# netx90_app register map
File version: 1.0
CPU: CM4 r0p1, little endian, MPU, FPU, 4 interrupt priority bits, 78 interrupts
Registers are 32-bit, read-write, reset 0x0 unless marked. A register's access mark holds for its fields unless they carry their own. Offsets are from the block's base; [hi:lo] are bit positions; {n}, {i} and the like mark numbered series; 'fields as' and 'values as' point back to an identical list.

## pad_ctrl
Base 0xFF401000
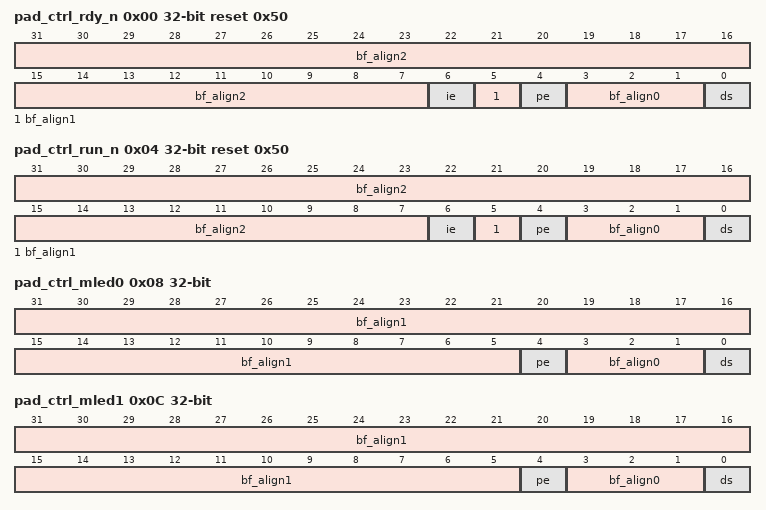
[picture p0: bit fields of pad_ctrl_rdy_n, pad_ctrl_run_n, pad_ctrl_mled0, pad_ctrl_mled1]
0x00 pad_ctrl_rdy_n reset 0x50 (reset mask 0x51) — Pad configuration register of port RDY_N (asic_ctrl_access_key protected). Pad type: PRUW0408SCDG_33 This register is protected by the netX access-key mechanism; changing this register is only possible by the following sequence: 1.: read out access-key from asic_ctrl_access_key register 2.: write back access-key to asic_ctrl_access_key register 3.: write desired value to this register Programable pad functions are: ds: Driving strength: 0: low driving strength (default), 1: high driving strength. pe: Pull enable: 0: No resistor is applied, 1: resistor is enabled. The pull-direction (up or down) is determined by the pad-type. ie: Input enable: 0: Digital pad input function disabled, 1: input is enabled. Note: Not all functions are available for all pads, it depends on the pad type. Functions not found as programmable bit in the register of a pad are not supported by the pad. Note: During a power cycle (power up or when a power watch detects an invalid supply), all IOs are undriven (output enable is off). Additionally the following states are forced to the IOs (POC-states): pe: 0 Attention: the internal push/pull resistors are not applied during a power cycle. ds: 1 (no impact as outputs are disabled) ie: 0 (no impact as core is in reset) After all power watches have detected a stable power state, the netX enters the reset state. At that moment the default values of the PAD_CTRL registers will be applied to the IOs.
  [31:7] bf_align2 — bitField alignment value for aeabi compatibility
  [6] ie — input enable (enabled by default)
  [5] bf_align1 — bitField alignment value for aeabi compatibility
  [4] pe — pull enable (pull-up pad, enabled by default)
  [3:1] bf_align0 — bitField alignment value for aeabi compatibility
  [0] ds — driving strength (low by default)
0x04 pad_ctrl_run_n reset 0x50 (reset mask 0x51) — Pad configuration register of port RUN_N (asic_ctrl_access_key protected). Pad type: PRUW0408SCDG_33 For details refer to description of register pad_ctrl_rdy_n.
  fields as pad_ctrl_rdy_n
0x08 pad_ctrl_mled0 (reset mask 0x11) — Pad configuration register of port MLED0 (asic_ctrl_access_key protected). Pad type: PRDW0408CDG_33(o_sc) For details refer to description of register pad_ctrl_rdy_n.
  [31:5] bf_align1 — bitField alignment value for aeabi compatibility
  [4] pe — pull enable (pull-down pad, disabled by default)
  [3:1] bf_align0 — bitField alignment value for aeabi compatibility
  [0] ds — driving strength (low by default)
0x0C pad_ctrl_mled1 (reset mask 0x11) — Pad configuration register of port MLED1 (asic_ctrl_access_key protected). Pad type: PRDW0408CDG_33(o_sc) For details refer to description of register pad_ctrl_rdy_n.
  fields as pad_ctrl_mled0
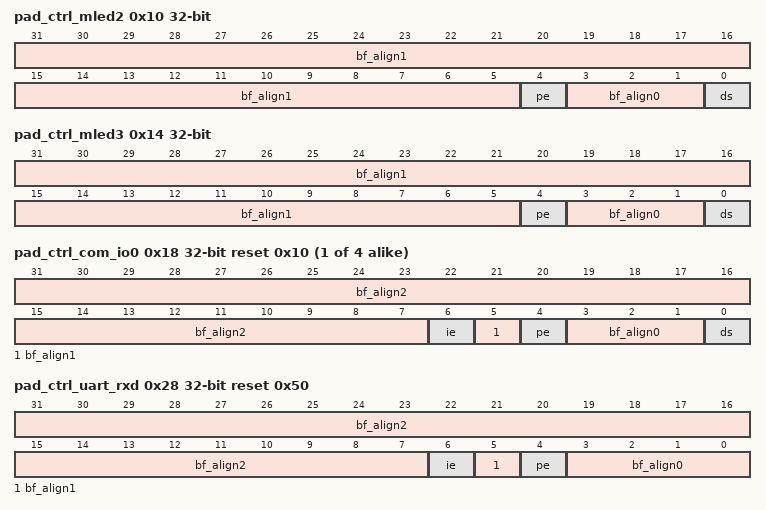
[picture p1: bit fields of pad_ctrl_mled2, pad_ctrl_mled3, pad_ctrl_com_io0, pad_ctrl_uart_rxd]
0x10 pad_ctrl_mled2 (reset mask 0x11) — Pad configuration register of port MLED2 (asic_ctrl_access_key protected). Pad type: PRDW0408CDG_33(o) For details refer to description of register pad_ctrl_rdy_n.
  fields as pad_ctrl_mled0
0x14 pad_ctrl_mled3 (reset mask 0x11) — Pad configuration register of port MLED3 (asic_ctrl_access_key protected). Pad type: PRDW0408CDG_33(o) For details refer to description of register pad_ctrl_rdy_n.
  fields as pad_ctrl_mled0
{0x18+4i} pad_ctrl_com_io{i} reset 0x10 (reset mask 0x51) (i=0..3) — Pad configuration register of port COM_IO{i} (asic_ctrl_access_key protected). Pad type: PRDW0408SCDG_ANA_SW_33(adc3) For details refer to description of register pad_ctrl_rdy_n.
  [31:7] bf_align2 — bitField alignment value for aeabi compatibility
  [6] ie — input enable (shared analog function, disabled by default)
  [5] bf_align1 — bitField alignment value for aeabi compatibility
  [4] pe — pull enable (pull-down pad, enabled by default)
  [3:1] bf_align0 — bitField alignment value for aeabi compatibility
  [0] ds — driving strength (low by default)
0x28 pad_ctrl_uart_rxd reset 0x50 (reset mask 0x50) — Pad configuration register of port UART_RXD (asic_ctrl_access_key protected). Pad type: PDDW0204SCDG_33(i) For details refer to description of register pad_ctrl_rdy_n.
  [31:7] bf_align2 — bitField alignment value for aeabi compatibility
  [6] ie — input enable (enabled by default)
  [5] bf_align1 — bitField alignment value for aeabi compatibility
  [4] pe — pull enable (pull-down pad, enabled by default)
  [3:0] bf_align0 — bitField alignment value for aeabi compatibility
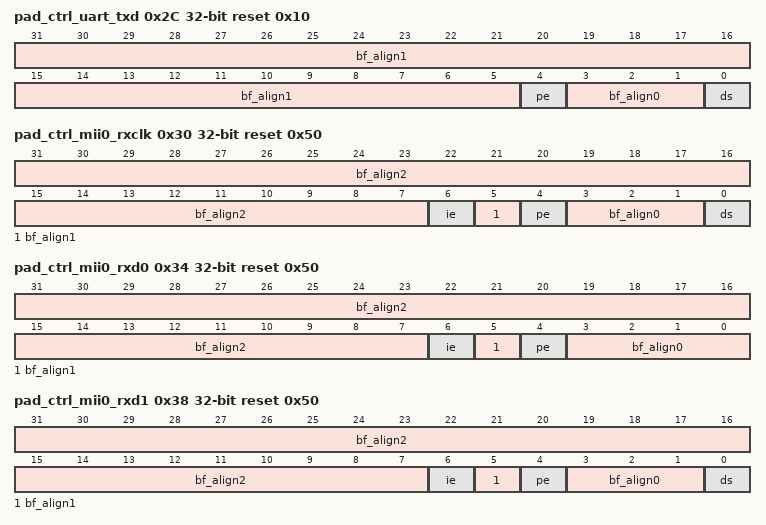
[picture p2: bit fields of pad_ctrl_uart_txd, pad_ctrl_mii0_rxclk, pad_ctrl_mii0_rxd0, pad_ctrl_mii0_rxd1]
0x2C pad_ctrl_uart_txd reset 0x10 (reset mask 0x11) — Pad configuration register of port UART_TXD (asic_ctrl_access_key protected). Pad type: PRDW0408CDG_33(o) For details refer to description of register pad_ctrl_rdy_n.
  [31:5] bf_align1 — bitField alignment value for aeabi compatibility
  [4] pe — pull enable (pull-down pad, enabled by default)
  [3:1] bf_align0 — bitField alignment value for aeabi compatibility
  [0] ds — driving strength (low by default)
0x30 pad_ctrl_mii0_rxclk reset 0x50 (reset mask 0x51) — Pad configuration register of port MII0_RXCLK (asic_ctrl_access_key protected). Pad type: PRDW0408SCDG_33 For details refer to description of register pad_ctrl_rdy_n.
  [31:7] bf_align2 — bitField alignment value for aeabi compatibility
  [6] ie — input enable (enabled by default)
  [5] bf_align1 — bitField alignment value for aeabi compatibility
  [4] pe — pull enable (pull-down pad, enabled by default)
  [3:1] bf_align0 — bitField alignment value for aeabi compatibility
  [0] ds — driving strength (low by default)
0x34 pad_ctrl_mii0_rxd0 reset 0x50 (reset mask 0x50) — Pad configuration register of port MII0_RXD0 (asic_ctrl_access_key protected). Pad type: PDDW0204SCDG_33(i) For details refer to description of register pad_ctrl_rdy_n.
  fields as pad_ctrl_uart_rxd
0x38 pad_ctrl_mii0_rxd1 reset 0x50 (reset mask 0x51) — Pad configuration register of port MII0_RXD1 (asic_ctrl_access_key protected). Pad type: PDDW0408SCDG_33 For details refer to description of register pad_ctrl_rdy_n.
  fields as pad_ctrl_mii0_rxclk
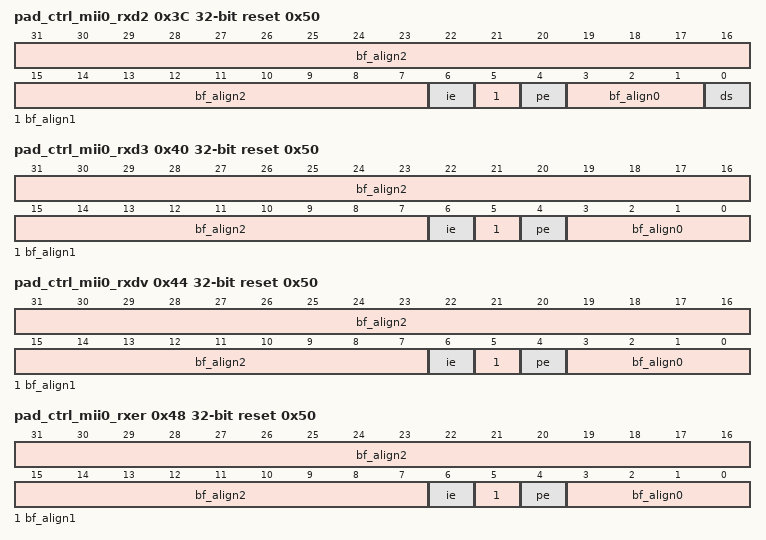
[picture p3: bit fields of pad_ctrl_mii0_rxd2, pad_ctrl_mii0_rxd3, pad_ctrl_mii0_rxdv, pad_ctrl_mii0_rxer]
0x3C pad_ctrl_mii0_rxd2 reset 0x50 (reset mask 0x51) — Pad configuration register of port MII0_RXD2 (asic_ctrl_access_key protected). Pad type: PRDW0408SCDG_33 For details refer to description of register pad_ctrl_rdy_n.
  fields as pad_ctrl_mii0_rxclk
0x40 pad_ctrl_mii0_rxd3 reset 0x50 (reset mask 0x50) — Pad configuration register of port MII0_RXD3 (asic_ctrl_access_key protected). Pad type: PDDW0204SCDG_33(i) For details refer to description of register pad_ctrl_rdy_n.
  fields as pad_ctrl_uart_rxd
0x44 pad_ctrl_mii0_rxdv reset 0x50 (reset mask 0x50) — Pad configuration register of port MII0_RXDV (asic_ctrl_access_key protected). Pad type: PDDW0204SCDG_33(i) For details refer to description of register pad_ctrl_rdy_n.
  fields as pad_ctrl_uart_rxd
0x48 pad_ctrl_mii0_rxer reset 0x50 (reset mask 0x50) — Pad configuration register of port MII0_RXER (asic_ctrl_access_key protected). Pad type: PDDW0204SCDG_33(i) For details refer to description of register pad_ctrl_rdy_n.
  fields as pad_ctrl_uart_rxd
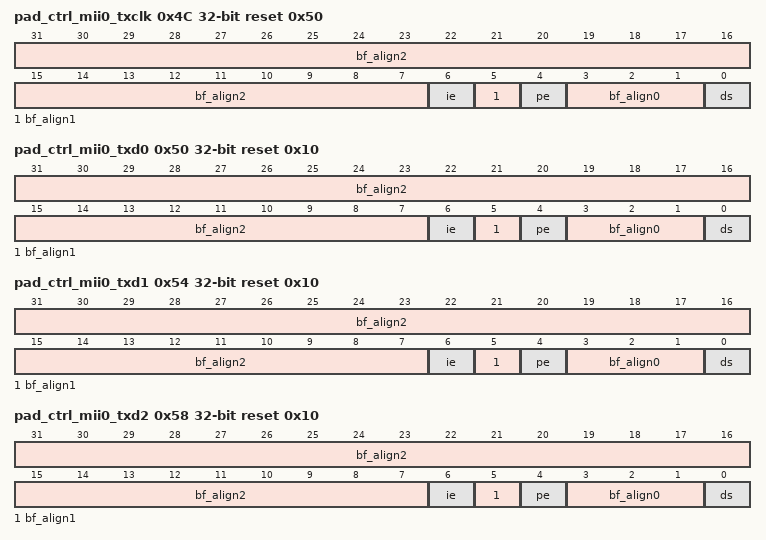
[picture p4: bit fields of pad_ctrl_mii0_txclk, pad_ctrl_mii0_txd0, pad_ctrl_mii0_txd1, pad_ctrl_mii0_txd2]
0x4C pad_ctrl_mii0_txclk reset 0x50 (reset mask 0x51) — Pad configuration register of port MII0_TXCLK (asic_ctrl_access_key protected). Pad type: PRDW0408SCDG_33 For details refer to description of register pad_ctrl_rdy_n.
  fields as pad_ctrl_mii0_rxclk
0x50 pad_ctrl_mii0_txd0 reset 0x10 (reset mask 0x51) — Pad configuration register of port MII0_TXD0 (asic_ctrl_access_key protected). Pad type: PRDW0408SCDG_ANA_SW_33(adc2) For details refer to description of register pad_ctrl_rdy_n.
  fields as pad_ctrl_com_io0
0x54 pad_ctrl_mii0_txd1 reset 0x10 (reset mask 0x51) — Pad configuration register of port MII0_TXD1 (asic_ctrl_access_key protected). Pad type: PRDW0408SCDG_ANA_SW_33(adc3) For details refer to description of register pad_ctrl_rdy_n.
  fields as pad_ctrl_com_io0
0x58 pad_ctrl_mii0_txd2 reset 0x10 (reset mask 0x51) — Pad configuration register of port MII0_TXD2 (asic_ctrl_access_key protected). Pad type: PRDW0408SCDG_ANA_SW_33(adc2) For details refer to description of register pad_ctrl_rdy_n.
  fields as pad_ctrl_com_io0
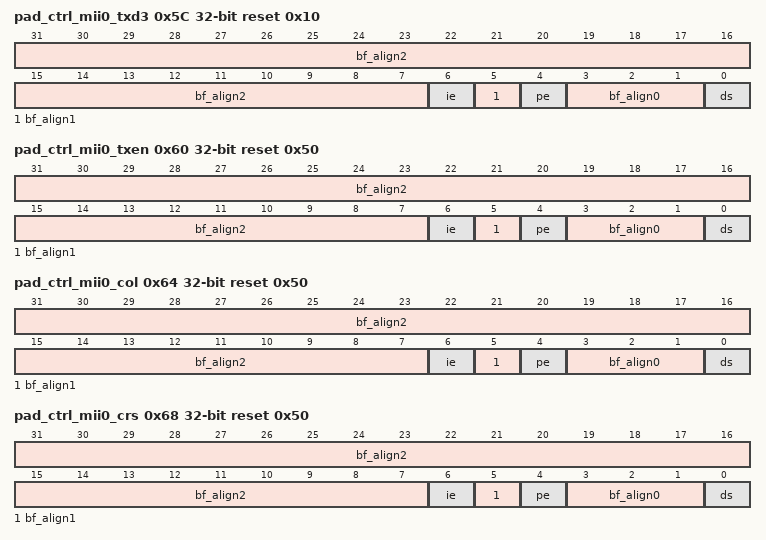
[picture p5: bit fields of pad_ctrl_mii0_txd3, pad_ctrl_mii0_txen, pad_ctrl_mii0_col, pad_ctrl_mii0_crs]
0x5C pad_ctrl_mii0_txd3 reset 0x10 (reset mask 0x51) — Pad configuration register of port MII0_TXD3 (asic_ctrl_access_key protected). Pad type: PRDW0408SCDG_ANA_SW_33(adc3) For details refer to description of register pad_ctrl_rdy_n.
  fields as pad_ctrl_com_io0
0x60 pad_ctrl_mii0_txen reset 0x50 (reset mask 0x51) — Pad configuration register of port MII0_TXEN (asic_ctrl_access_key protected). Pad type: PDDW0408SCDG_33 For details refer to description of register pad_ctrl_rdy_n.
  fields as pad_ctrl_mii0_rxclk
0x64 pad_ctrl_mii0_col reset 0x50 (reset mask 0x51) — Pad configuration register of port MII0_COL (asic_ctrl_access_key protected). Pad type: PDDW0408SCDG_33 For details refer to description of register pad_ctrl_rdy_n.
  fields as pad_ctrl_mii0_rxclk
0x68 pad_ctrl_mii0_crs reset 0x50 (reset mask 0x51) — Pad configuration register of port MII0_CRS (asic_ctrl_access_key protected). Pad type: PDDW0408SCDG_33 For details refer to description of register pad_ctrl_rdy_n.
  fields as pad_ctrl_mii0_rxclk
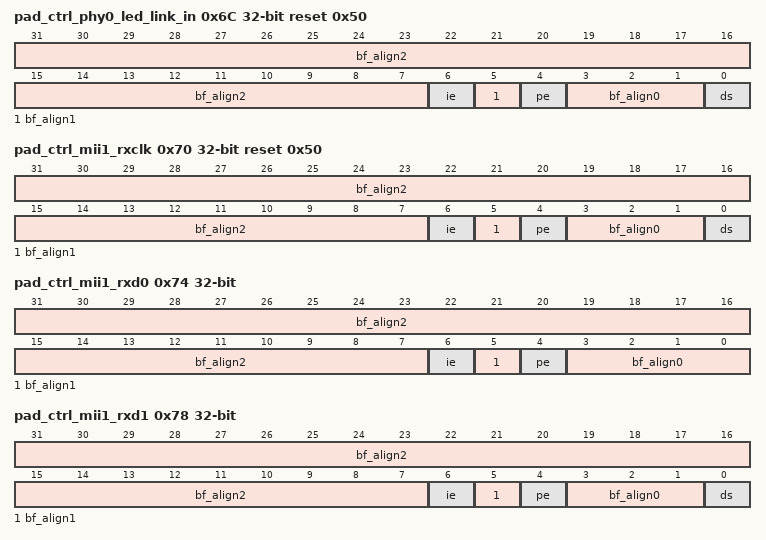
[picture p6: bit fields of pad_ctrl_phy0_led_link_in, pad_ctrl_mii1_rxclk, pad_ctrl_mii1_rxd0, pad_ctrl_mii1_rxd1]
0x6C pad_ctrl_phy0_led_link_in reset 0x50 (reset mask 0x51) — Pad configuration register of port PHY0_LED_LINK_IN (asic_ctrl_access_key protected). Pad type: PDDW0408SCDG_33 For details refer to description of register pad_ctrl_rdy_n.
  fields as pad_ctrl_mii0_rxclk
0x70 pad_ctrl_mii1_rxclk reset 0x50 (reset mask 0x51) — Pad configuration register of port MII1_RXCLK (asic_ctrl_access_key protected). Pad type: PRDW0408SCDG_33 For details refer to description of register pad_ctrl_rdy_n.
  fields as pad_ctrl_mii0_rxclk
0x74 pad_ctrl_mii1_rxd0 (reset mask 0x50) — Pad configuration register of port MII1_RXD0 (asic_ctrl_access_key protected). Pad type: PDDW0204SCDG_33(i_double_bond) For details refer to description of register pad_ctrl_rdy_n.
  [31:7] bf_align2 — bitField alignment value for aeabi compatibility
  [6] ie — input enable (disabled by default)
  [5] bf_align1 — bitField alignment value for aeabi compatibility
  [4] pe — pull enable (pull-down pad, disabled by default)
  [3:0] bf_align0 — bitField alignment value for aeabi compatibility
0x78 pad_ctrl_mii1_rxd1 (reset mask 0x51) — Pad configuration register of port MII1_RXD1 (asic_ctrl_access_key protected). Pad type: PDDW0408SCDG_33(double_bond) For details refer to description of register pad_ctrl_rdy_n.
  [31:7] bf_align2 — bitField alignment value for aeabi compatibility
  [6] ie — input enable (disabled by default)
  [5] bf_align1 — bitField alignment value for aeabi compatibility
  [4] pe — pull enable (pull-down pad, disabled by default)
  [3:1] bf_align0 — bitField alignment value for aeabi compatibility
  [0] ds — driving strength (low by default)
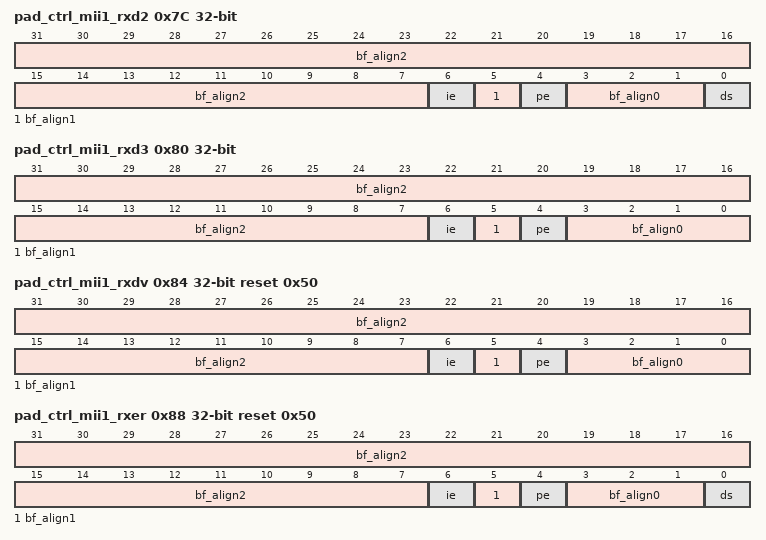
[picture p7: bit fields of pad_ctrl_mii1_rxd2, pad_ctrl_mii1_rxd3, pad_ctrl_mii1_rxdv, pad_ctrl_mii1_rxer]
0x7C pad_ctrl_mii1_rxd2 (reset mask 0x51) — Pad configuration register of port MII1_RXD2 (asic_ctrl_access_key protected). Pad type: PRDW0408SCDG_33(double_bond) For details refer to description of register pad_ctrl_rdy_n.
  fields as pad_ctrl_mii1_rxd1
0x80 pad_ctrl_mii1_rxd3 (reset mask 0x50) — Pad configuration register of port MII1_RXD3 (asic_ctrl_access_key protected). Pad type: PDDW0204SCDG_33(i_double_bond) For details refer to description of register pad_ctrl_rdy_n.
  fields as pad_ctrl_mii1_rxd0
0x84 pad_ctrl_mii1_rxdv reset 0x50 (reset mask 0x50) — Pad configuration register of port MII1_RXDV (asic_ctrl_access_key protected). Pad type: PDDW0204SCDG_33(i) For details refer to description of register pad_ctrl_rdy_n.
  fields as pad_ctrl_uart_rxd
0x88 pad_ctrl_mii1_rxer reset 0x50 (reset mask 0x51) — Pad configuration register of port MII1_RXER (asic_ctrl_access_key protected). Pad type: PDDW0408SCDG_33 For details refer to description of register pad_ctrl_rdy_n.
  fields as pad_ctrl_mii0_rxclk
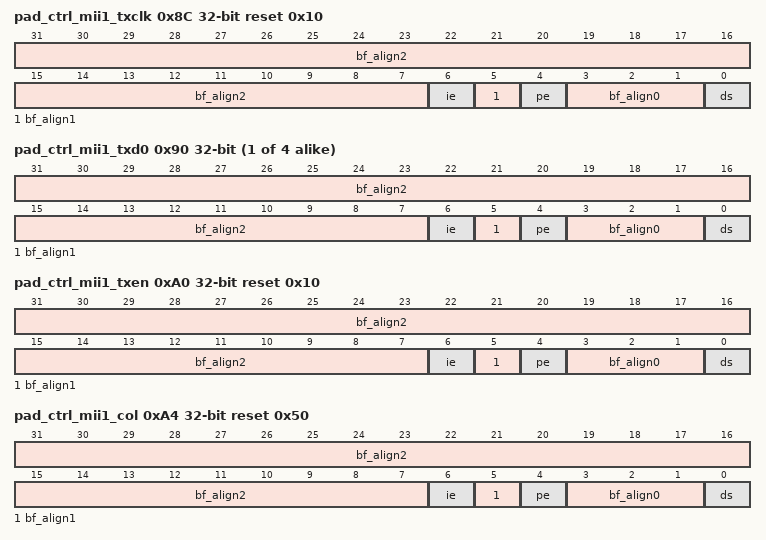
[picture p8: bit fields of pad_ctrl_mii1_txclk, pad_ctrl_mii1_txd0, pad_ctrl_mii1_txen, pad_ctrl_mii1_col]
0x8C pad_ctrl_mii1_txclk reset 0x10 (reset mask 0x51) — Pad configuration register of port MII1_TXCLK (asic_ctrl_access_key protected). Pad type: PRDW0408SCDG_ANA_SW_33(adc2) For details refer to description of register pad_ctrl_rdy_n.
  fields as pad_ctrl_com_io0
{0x90+4i} pad_ctrl_mii1_txd{i} (reset mask 0x51) (i=0..3) — Pad configuration register of port MII1_TXD{i} (asic_ctrl_access_key protected). Pad type: PRDW0408SCDG_33(double_bond) For details refer to description of register pad_ctrl_rdy_n.
  fields as pad_ctrl_mii1_rxd1
0xA0 pad_ctrl_mii1_txen reset 0x10 (reset mask 0x51) — Pad configuration register of port MII1_TXEN (asic_ctrl_access_key protected). Pad type: PRDW0408SCDG_ANA_SW_33(adc2) For details refer to description of register pad_ctrl_rdy_n.
  fields as pad_ctrl_com_io0
0xA4 pad_ctrl_mii1_col reset 0x50 (reset mask 0x51) — Pad configuration register of port MII1_COL (asic_ctrl_access_key protected). Pad type: PDDW0408SCDG_33 For details refer to description of register pad_ctrl_rdy_n.
  fields as pad_ctrl_mii0_rxclk
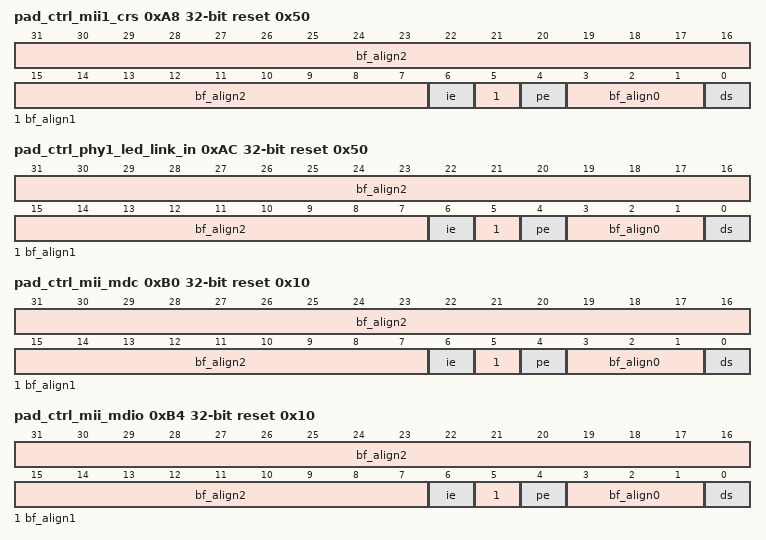
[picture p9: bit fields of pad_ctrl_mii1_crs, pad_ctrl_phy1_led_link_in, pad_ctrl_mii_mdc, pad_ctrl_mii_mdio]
0xA8 pad_ctrl_mii1_crs reset 0x50 (reset mask 0x51) — Pad configuration register of port MII1_CRS (asic_ctrl_access_key protected). Pad type: PDDW0408SCDG_33 For details refer to description of register pad_ctrl_rdy_n.
  fields as pad_ctrl_mii0_rxclk
0xAC pad_ctrl_phy1_led_link_in reset 0x50 (reset mask 0x51) — Pad configuration register of port PHY1_LED_LINK_IN (asic_ctrl_access_key protected). Pad type: PDDW0408SCDG_33 For details refer to description of register pad_ctrl_rdy_n.
  fields as pad_ctrl_mii0_rxclk
0xB0 pad_ctrl_mii_mdc reset 0x10 (reset mask 0x51) — Pad configuration register of port MII_MDC (asic_ctrl_access_key protected). Pad type: PRDW0408SCDG_ANA_SW_33(adc2) For details refer to description of register pad_ctrl_rdy_n.
  fields as pad_ctrl_com_io0
0xB4 pad_ctrl_mii_mdio reset 0x10 (reset mask 0x51) — Pad configuration register of port MII_MDIO (asic_ctrl_access_key protected). Pad type: PRDW0408SCDG_ANA_SW_33(adc2) For details refer to description of register pad_ctrl_rdy_n.
  fields as pad_ctrl_com_io0
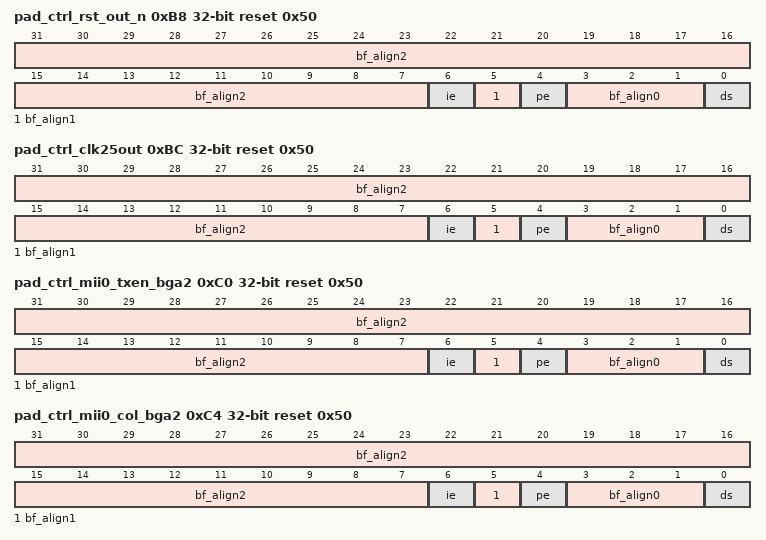
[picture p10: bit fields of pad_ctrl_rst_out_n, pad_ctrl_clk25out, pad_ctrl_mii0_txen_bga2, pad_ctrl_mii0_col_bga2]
0xB8 pad_ctrl_rst_out_n reset 0x50 (reset mask 0x51) — Pad configuration register of port RST_OUT_N (asic_ctrl_access_key protected). Pad type: PRDW0408SCDG_33 For details refer to description of register pad_ctrl_rdy_n.
  fields as pad_ctrl_mii0_rxclk
0xBC pad_ctrl_clk25out reset 0x50 (reset mask 0x51) — Pad configuration register of port CLK25OUT (asic_ctrl_access_key protected). Pad type: PDDW0408SCDG_33 For details refer to description of register pad_ctrl_rdy_n.
  fields as pad_ctrl_mii0_rxclk
0xC0 pad_ctrl_mii0_txen_bga2 reset 0x50 (reset mask 0x51) — Pad configuration register of port MII0_TXEN_BGA2 (asic_ctrl_access_key protected). Pad type: PRDW0408SCDG_33 For details refer to description of register pad_ctrl_rdy_n.
  fields as pad_ctrl_mii0_rxclk
0xC4 pad_ctrl_mii0_col_bga2 reset 0x50 (reset mask 0x51) — Pad configuration register of port MII0_COL_BGA2 (asic_ctrl_access_key protected). Pad type: PRDW0408SCDG_33 For details refer to description of register pad_ctrl_rdy_n.
  fields as pad_ctrl_mii0_rxclk
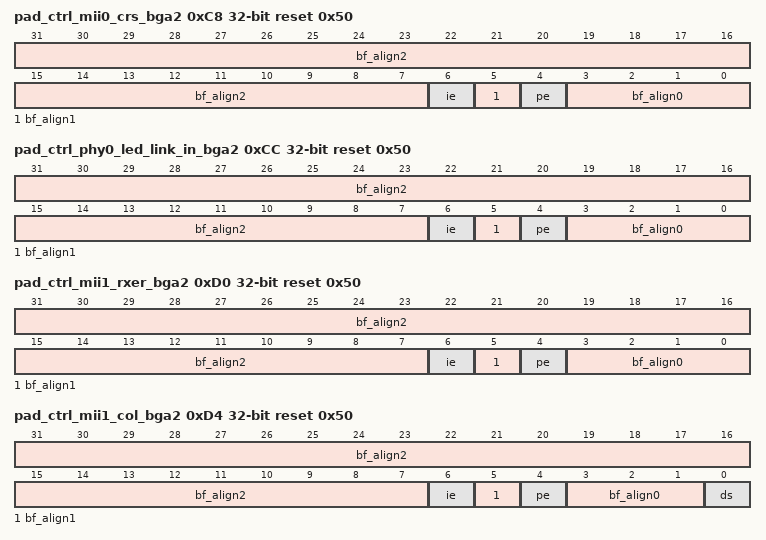
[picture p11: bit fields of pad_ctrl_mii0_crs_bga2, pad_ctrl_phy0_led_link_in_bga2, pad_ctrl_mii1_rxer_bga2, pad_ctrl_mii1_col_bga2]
0xC8 pad_ctrl_mii0_crs_bga2 reset 0x50 (reset mask 0x50) — Pad configuration register of port MII0_CRS_BGA2 (asic_ctrl_access_key protected). Pad type: PDDW0204SCDG_33(i) For details refer to description of register pad_ctrl_rdy_n.
  fields as pad_ctrl_uart_rxd
0xCC pad_ctrl_phy0_led_link_in_bga2 reset 0x50 (reset mask 0x50) — Pad configuration register of port PHY0_LED_LINK_IN_BGA2 (asic_ctrl_access_key protected). Pad type: PDDW0204SCDG_33(i) For details refer to description of register pad_ctrl_rdy_n.
  fields as pad_ctrl_uart_rxd
0xD0 pad_ctrl_mii1_rxer_bga2 reset 0x50 (reset mask 0x50) — Pad configuration register of port MII1_RXER_BGA2 (asic_ctrl_access_key protected). Pad type: PDDW0204SCDG_33(i) For details refer to description of register pad_ctrl_rdy_n.
  fields as pad_ctrl_uart_rxd
0xD4 pad_ctrl_mii1_col_bga2 reset 0x50 (reset mask 0x51) — Pad configuration register of port MII1_COL_BGA2 (asic_ctrl_access_key protected). Pad type: PRDW0408SCDG_33 For details refer to description of register pad_ctrl_rdy_n.
  fields as pad_ctrl_mii0_rxclk
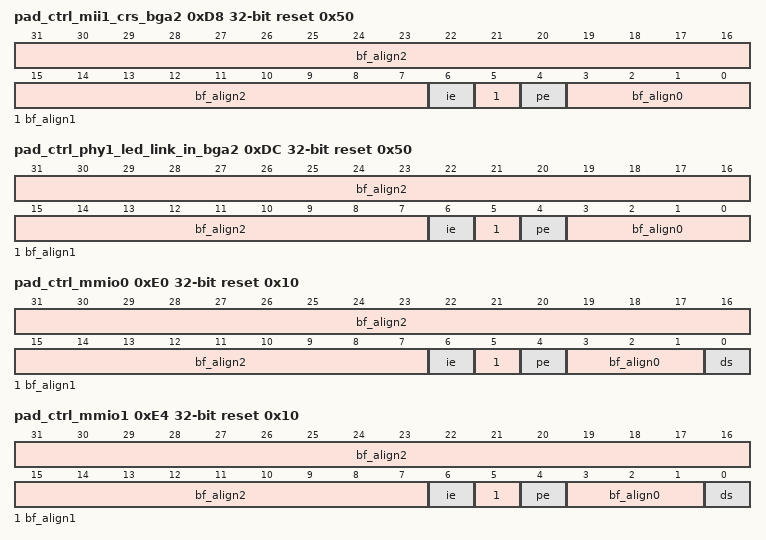
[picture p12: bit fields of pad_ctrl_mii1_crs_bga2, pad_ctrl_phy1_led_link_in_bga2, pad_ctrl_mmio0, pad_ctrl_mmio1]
0xD8 pad_ctrl_mii1_crs_bga2 reset 0x50 (reset mask 0x50) — Pad configuration register of port MII1_CRS_BGA2 (asic_ctrl_access_key protected). Pad type: PDDW0204SCDG_33(i) For details refer to description of register pad_ctrl_rdy_n.
  fields as pad_ctrl_uart_rxd
0xDC pad_ctrl_phy1_led_link_in_bga2 reset 0x50 (reset mask 0x50) — Pad configuration register of port PHY1_LED_LINK_IN_BGA2 (asic_ctrl_access_key protected). Pad type: PDDW0204SCDG_33(i) For details refer to description of register pad_ctrl_rdy_n.
  fields as pad_ctrl_uart_rxd
0xE0 pad_ctrl_mmio0 reset 0x10 (reset mask 0x51) — Pad configuration register of port MMIO0 (asic_ctrl_access_key protected). Pad type: PRDW0408SCDG_ANA_SW_33(adc2) For details refer to description of register pad_ctrl_rdy_n.
  fields as pad_ctrl_com_io0
0xE4 pad_ctrl_mmio1 reset 0x10 (reset mask 0x51) — Pad configuration register of port MMIO1 (asic_ctrl_access_key protected). Pad type: PRDW0408SCDG_ANA_SW_33(adc2) For details refer to description of register pad_ctrl_rdy_n.
  fields as pad_ctrl_com_io0
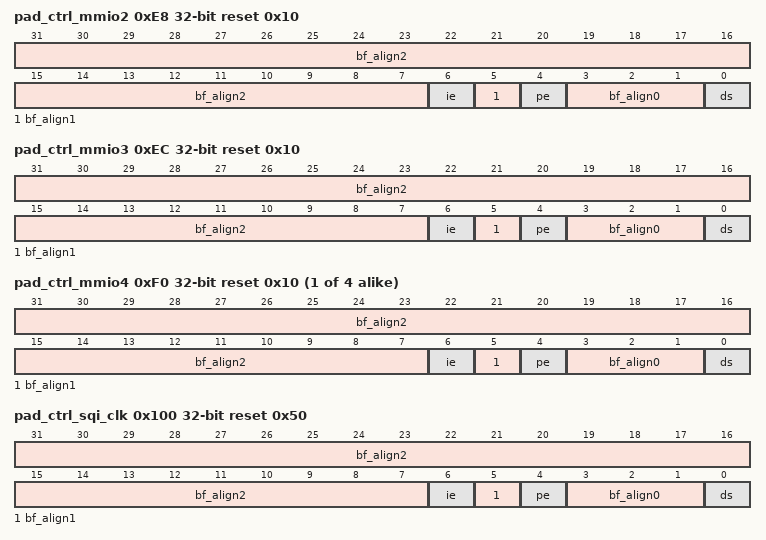
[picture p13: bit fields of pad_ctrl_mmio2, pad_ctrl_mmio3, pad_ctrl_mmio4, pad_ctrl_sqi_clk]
0xE8 pad_ctrl_mmio2 reset 0x10 (reset mask 0x51) — Pad configuration register of port MMIO2 (asic_ctrl_access_key protected). Pad type: PRDW0408SCDG_ANA_SW_33(adc3) For details refer to description of register pad_ctrl_rdy_n.
  fields as pad_ctrl_com_io0
0xEC pad_ctrl_mmio3 reset 0x10 (reset mask 0x51) — Pad configuration register of port MMIO3 (asic_ctrl_access_key protected). Pad type: PRDW0408SCDG_ANA_SW_33(adc3) For details refer to description of register pad_ctrl_rdy_n.
  fields as pad_ctrl_com_io0
{0xE0+4i} pad_ctrl_mmio{i} reset 0x10 (reset mask 0x51) (i=4..7) — Pad configuration register of port MMIO{i} (asic_ctrl_access_key protected). Pad type: PRDW0408SCDG_ANA_33 For details refer to description of register pad_ctrl_rdy_n.
  fields as pad_ctrl_com_io0
0x100 pad_ctrl_sqi_clk reset 0x50 (reset mask 0x51) — Pad configuration register of port SQI_CLK (asic_ctrl_access_key protected). Pad type: PDUW0408SCDG_33 For details refer to description of register pad_ctrl_rdy_n.
  fields as pad_ctrl_rdy_n
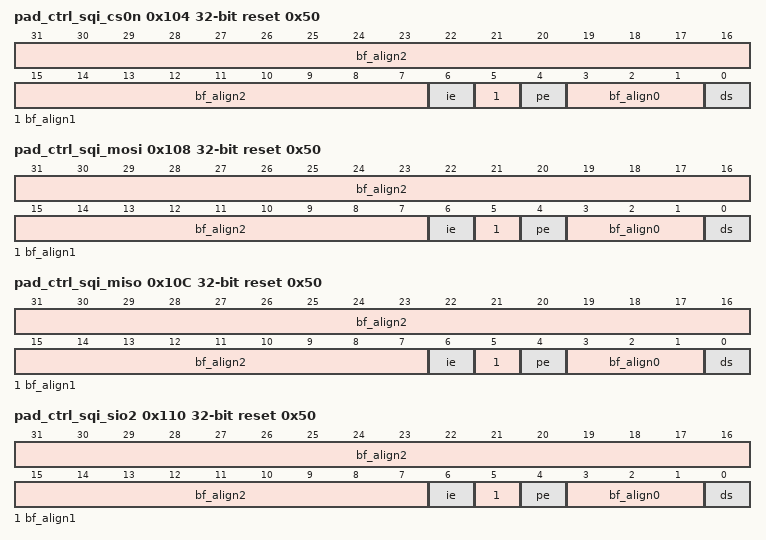
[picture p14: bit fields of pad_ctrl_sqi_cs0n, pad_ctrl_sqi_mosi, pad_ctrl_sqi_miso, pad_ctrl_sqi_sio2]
0x104 pad_ctrl_sqi_cs0n reset 0x50 (reset mask 0x51) — Pad configuration register of port SQI_CS0N (asic_ctrl_access_key protected). Pad type: PDUW0408SCDG_33 For details refer to description of register pad_ctrl_rdy_n.
  fields as pad_ctrl_rdy_n
0x108 pad_ctrl_sqi_mosi reset 0x50 (reset mask 0x51) — Pad configuration register of port SQI_MOSI (asic_ctrl_access_key protected). Pad type: PDUW0408SCDG_33 For details refer to description of register pad_ctrl_rdy_n.
  fields as pad_ctrl_rdy_n
0x10C pad_ctrl_sqi_miso reset 0x50 (reset mask 0x51) — Pad configuration register of port SQI_MISO (asic_ctrl_access_key protected). Pad type: PDUW0408SCDG_33 For details refer to description of register pad_ctrl_rdy_n.
  fields as pad_ctrl_rdy_n
0x110 pad_ctrl_sqi_sio2 reset 0x50 (reset mask 0x51) — Pad configuration register of port SQI_SIO2 (asic_ctrl_access_key protected). Pad type: PDUW0408SCDG_33 For details refer to description of register pad_ctrl_rdy_n.
  fields as pad_ctrl_rdy_n
0x114 pad_ctrl_sqi_sio3 reset 0x50 (reset mask 0x51) — Pad configuration register of port SQI_SIO3 (asic_ctrl_access_key protected). Pad type: PDUW0408SCDG_33 For details refer to description of register pad_ctrl_rdy_n.
  fields as pad_ctrl_rdy_n
{0x118+4i} pad_ctrl_hif_a{i} reset 0x50 (reset mask 0x51) (i=0..17) — Pad configuration register of port HIF_A{i} (asic_ctrl_access_key protected). Pad type: PDUW0408SCDG_33 For details refer to description of register pad_ctrl_rdy_n.
  fields as pad_ctrl_rdy_n
{0x160+4i} pad_ctrl_hif_d{i} reset 0x50 (reset mask 0x51) (i=0..8) — Pad configuration register of port HIF_D{i} (asic_ctrl_access_key protected). Pad type: PDUW0408SCDG_33 For details refer to description of register pad_ctrl_rdy_n.
  fields as pad_ctrl_rdy_n
{0x160+4i} pad_ctrl_hif_d{i} reset 0x50 (reset mask 0x51) (i=9..15) — Pad configuration register of port HIF_D{i} (asic_ctrl_access_key protected). Pad type: PRUW0408SCDG_33 For details refer to description of register pad_ctrl_rdy_n.
  fields as pad_ctrl_rdy_n
0x1A0 pad_ctrl_hif_bhen reset 0x50 (reset mask 0x51) — Pad configuration register of port HIF_BHEN (asic_ctrl_access_key protected). Pad type: PDUW0408SCDG_33 For details refer to description of register pad_ctrl_rdy_n.
  fields as pad_ctrl_rdy_n
0x1A4 pad_ctrl_hif_csn reset 0x50 (reset mask 0x51) — Pad configuration register of port HIF_CSN (asic_ctrl_access_key protected). Pad type: PDUW0408SCDG_33 For details refer to description of register pad_ctrl_rdy_n.
  fields as pad_ctrl_rdy_n
0x1A8 pad_ctrl_hif_rdn reset 0x50 (reset mask 0x51) — Pad configuration register of port HIF_RDN (asic_ctrl_access_key protected). Pad type: PDUW0408SCDG_33 For details refer to description of register pad_ctrl_rdy_n.
  fields as pad_ctrl_rdy_n
0x1AC pad_ctrl_hif_wrn reset 0x50 (reset mask 0x51) — Pad configuration register of port HIF_WRN (asic_ctrl_access_key protected). Pad type: PDUW0408SCDG_33 For details refer to description of register pad_ctrl_rdy_n.
  fields as pad_ctrl_rdy_n
0x1B0 pad_ctrl_hif_rdy reset 0x50 (reset mask 0x51) — Pad configuration register of port HIF_RDY (asic_ctrl_access_key protected). Pad type: PDUW0408SCDG_33 For details refer to description of register pad_ctrl_rdy_n.
  fields as pad_ctrl_rdy_n
0x1B4 pad_ctrl_hif_dirq reset 0x50 (reset mask 0x51) — Pad configuration register of port HIF_DIRQ (asic_ctrl_access_key protected). Pad type: PDUW0408SCDG_33 For details refer to description of register pad_ctrl_rdy_n.
  fields as pad_ctrl_rdy_n
0x1B8 pad_ctrl_hif_sdclk reset 0x50 (reset mask 0x51) — Pad configuration register of port HIF_SDCLK (asic_ctrl_access_key protected). Pad type: PDUW0408SCDG_33 For details refer to description of register pad_ctrl_rdy_n.
  fields as pad_ctrl_rdy_n
